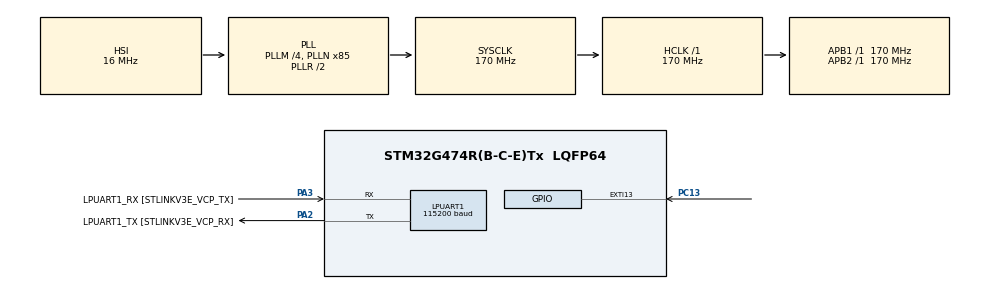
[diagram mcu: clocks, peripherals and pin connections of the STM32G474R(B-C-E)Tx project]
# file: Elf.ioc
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LPUART1.BaudRate=115200
Mcu.Family=STM32G4
Mcu.Name=STM32G474R(B-C-E)Tx
Mcu.Package=LQFP64
NVIC.EXTI15_10_IRQn=true\:0\:0\:false\:false\:false\:true\:true\:true
NVIC.PriorityGroup=NVIC_PRIORITYGROUP_4
NVIC.TIM3_IRQn=true\:0\:0\:false\:false\:false\:true\:true\:true
PA13.GPIO_Label=T_SWDIO
PA13.Signal=SYS_JTMS-SWDIO
PA14.GPIO_Label=T_SWCLK
PA14.Signal=SYS_JTCK-SWCLK
PA2.GPIO_Label=LPUART1_TX [STLINKV3E_VCP_RX]
PA2.Mode=Asynchronous
PA2.Signal=LPUART1_TX
PA3.GPIO_Label=LPUART1_RX [STLINKV3E_VCP_TX]
PA3.Mode=Asynchronous
PA3.Signal=LPUART1_RX
PA5.Signal=S_TIM2_CH1
PB3.GPIO_Label=T_SWO
PB3.Signal=SYS_JTDO-SWO
PC13.Signal=GPXTI13
PC14-OSC32_IN.GPIO_Label=RCC_OSC32_IN
PC14-OSC32_IN.Signal=RCC_OSC32_IN
PC15-OSC32_OUT.GPIO_Label=RCC_OSC32_OUT
PC15-OSC32_OUT.Signal=RCC_OSC32_OUT
PF0-OSC_IN.GPIO_Label=RCC_OSC_IN
PF0-OSC_IN.Signal=RCC_OSC_IN
PF1-OSC_OUT.GPIO_Label=RCC_OSC_OUT
PF1-OSC_OUT.Signal=RCC_OSC_OUT
ProjectManager.HeapSize=0x200
ProjectManager.StackSize=0x400
ProjectManager.TargetToolchain=STM32CubeIDE
RCC.ADC12Freq_Value=170000000
RCC.ADC345Freq_Value=170000000
RCC.AHBFreq_Value=170000000
RCC.APB1Freq_Value=170000000
RCC.APB1TimFreq_Value=170000000
RCC.APB2Freq_Value=170000000
RCC.APB2TimFreq_Value=170000000
RCC.CortexFreq_Value=170000000
RCC.EXTERNAL_CLOCK_VALUE=12288000
RCC.HCLKFreq_Value=170000000
RCC.HSE_VALUE=24000000
RCC.HSI48_VALUE=48000000
RCC.HSI_VALUE=16000000
RCC.LSE_VALUE=32768
RCC.PLLM=RCC_PLLM_DIV4
RCC.PLLN=85
RCC.RTCClockSelection=RCC_RTCCLKSOURCE_LSE
RCC.SYSCLKFreq_VALUE=170000000
RCC.SYSCLKSource=RCC_SYSCLKSOURCE_PLLCLK
RCC.USBFreq_Value=170000000
RCC.VCOOutputFreq_Value=340000000
SH.S_TIM2_CH1.0=TIM2_CH1
TIM2.Channel-PWM\ Generation1\ No\ Output=TIM_CHANNEL_1
VP_SYS_VS_DBSignals.Mode=DisableDeadBatterySignals
VP_TIM2_VS_ClockSourceINT.Mode=Internal
VP_TIM2_VS_no_output1.Mode=PWM Generation1 No Output
VP_TIM3_VS_ClockSourceINT.Mode=Internal
board=NUCLEO-G474RE

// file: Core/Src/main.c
/* USER CODE BEGIN Header */
/**
  ******************************************************************************
  * @file           : main.c
  * @brief          : Main program body
  ******************************************************************************
  * @attention
  *
  * Copyright (c) 2026 STMicroelectronics.
  * All rights reserved.
  *
  * This software is licensed under terms that can be found in the LICENSE file
  * in the root directory of this software component.
  * If no LICENSE file comes with this software, it is provided AS-IS.
  *
  ******************************************************************************
  */
/* USER CODE END Header */
#include "main.h"

/* USER CODE BEGIN Includes */
#include <stdio.h>
/* USER CODE END Includes */

/* USER CODE BEGIN PD */

typedef enum {
    HEALTHY,
    WARNING,
    ANGRY
} PetState;
/* USER CODE END PD */

UART_HandleTypeDef hlpuart1;

TIM_HandleTypeDef htim2;
TIM_HandleTypeDef htim3;

/* USER CODE BEGIN PV */

volatile uint32_t sedentary_sec = 0;
volatile uint8_t checkin_flag = 0;
/* USER CODE END PV */

void SystemClock_Config(void);
static void MX_GPIO_Init(void);
static void MX_TIM2_Init(void);
static void MX_TIM3_Init(void);
static void MX_LPUART1_UART_Init(void);

/* USER CODE BEGIN 0 */

void UART_SendString(char* str) {
    while (*str) {

        while ((LPUART1->ISR & USART_ISR_TXE) == 0) {}
        LPUART1->TDR = *str++;
    }
}

void TIM3_IRQHandler(void) {

    if (TIM3->SR & TIM_SR_UIF) {
        TIM3->SR &= ~TIM_SR_UIF;
        sedentary_sec++;
    }
}

void EXTI15_10_IRQHandler(void) {

    if (EXTI->PR1 & (1 << 13)) {
        EXTI->PR1 = (1 << 13);
        sedentary_sec = 0;
        checkin_flag = 1;
    }
}

void Set_LED_Speed(PetState state) {
    if (state == HEALTHY) {

        TIM2->PSC = 1700 - 1;
        TIM2->ARR = 1000 - 1;
    } else if (state == WARNING) {

        TIM2->PSC = 850 - 1;
        TIM2->ARR = 500 - 1;
    } else {

        TIM2->PSC = 170 - 1;
        TIM2->ARR = 100 - 1;
    }
}
/* USER CODE END 0 */

int main(void)
{

  /* MCU Configuration--------------------------------------------------------*/

  /* Reset of all peripherals, Initializes the Flash interface and the Systick. */
  HAL_Init();

  /* Configure the system clock */
  SystemClock_Config();

  /* Initialize all configured peripherals */
  MX_GPIO_Init();
  MX_TIM2_Init();
  MX_TIM3_Init();
  MX_LPUART1_UART_Init();
  /* USER CODE BEGIN 2 */
    /* USER CODE BEGIN 2 */
  HAL_Init();
  SystemClock_Config();
  MX_GPIO_Init();
  MX_LPUART1_UART_Init();

    TIM3->PSC = 17000 - 1;
    TIM3->ARR = 5000 - 1;
    TIM3->DIER |= TIM_DIER_UIE;
    TIM3->CR1 |= TIM_CR1_CEN;
    NVIC_EnableIRQ(TIM3_IRQn);
    NVIC_EnableIRQ(EXTI15_10_IRQn);

    Set_LED_Speed(HEALTHY);
    TIM2->EGR |= TIM_EGR_UG;

    TIM2->CCMR1 &= ~TIM_CCMR1_OC1M_Msk;
    TIM2->CCMR1 |= (0x6 << TIM_CCMR1_OC1M_Pos);
    TIM2->CCER |= TIM_CCER_CC1E;
    TIM2->CR1 |= TIM_CR1_CEN;

    for (volatile int i = 0; i < 500000; i++);
    UART_SendString("\r\n=== 久坐健康精靈 開機完成 ===\r\n");

    PetState current_state = HEALTHY;
    int32_t ccr_val = 0;
    int8_t ccr_step = 1;
  /* USER CODE END 2 */

  /* Infinite loop */
  while (1)
  {

    /* USER CODE BEGIN 3 */

	        if (checkin_flag) {
	            checkin_flag = 0;
	            if (current_state != HEALTHY) {
	                current_state = HEALTHY;
	                Set_LED_Speed(HEALTHY);
	                UART_SendString("感謝安撫！精靈已恢復健康，重新計時。\r\n");
	            }
	        }

	        if (sedentary_sec > 30 && current_state != ANGRY) {
	            current_state = ANGRY;
	            UART_SendString("【警告】精靈非常生氣！你已經坐超過 30 秒了！\r\n");
	        }
	        else if (sedentary_sec > 15 && sedentary_sec <= 30 && current_state == HEALTHY) {
	            current_state = WARNING;
	            UART_SendString("【提醒】精靈不開心了，久坐超過 15 秒，該起來喝水囉！\r\n");
	        }

	        if (current_state == HEALTHY) {
	            ccr_step = (ccr_step > 0) ? 1 : -1;
	        } else if (current_state == WARNING) {
	            ccr_step = (ccr_step > 0) ? 5 : -5;
	        } else {
	            ccr_step = (ccr_step > 0) ? 50 : -50;
	        }

	        ccr_val += ccr_step;

	        if (ccr_val >= 1000) {
	            ccr_val = 1000;
	            ccr_step = -ccr_step;
	        } else if (ccr_val <= 0) {
	            ccr_val = 0;
	            ccr_step = -ccr_step;
	        }

	        TIM2->CCR1 = ccr_val;

	        for (volatile int i = 0; i < 10000; i++);
  }
  /* USER CODE END 3 */
}

void SystemClock_Config(void)
{
  RCC_OscInitTypeDef RCC_OscInitStruct = {0};
  RCC_ClkInitTypeDef RCC_ClkInitStruct = {0};

  /** Configure the main internal regulator output voltage
  */
  HAL_PWREx_ControlVoltageScaling(PWR_REGULATOR_VOLTAGE_SCALE1_BOOST);

  /** Initializes the RCC Oscillators according to the specified parameters
  * in the RCC_OscInitTypeDef structure.
  */
  RCC_OscInitStruct.OscillatorType = RCC_OSCILLATORTYPE_HSI;
  RCC_OscInitStruct.HSIState = RCC_HSI_ON;
  RCC_OscInitStruct.HSICalibrationValue = RCC_HSICALIBRATION_DEFAULT;
  RCC_OscInitStruct.PLL.PLLState = RCC_PLL_ON;
  RCC_OscInitStruct.PLL.PLLSource = RCC_PLLSOURCE_HSI;
  RCC_OscInitStruct.PLL.PLLM = RCC_PLLM_DIV4;
  RCC_OscInitStruct.PLL.PLLN = 85;
  RCC_OscInitStruct.PLL.PLLP = RCC_PLLP_DIV2;
  RCC_OscInitStruct.PLL.PLLQ = RCC_PLLQ_DIV2;
  RCC_OscInitStruct.PLL.PLLR = RCC_PLLR_DIV2;
  if (HAL_RCC_OscConfig(&RCC_OscInitStruct) != HAL_OK)
  {
    Error_Handler();
  }

  /** Initializes the CPU, AHB and APB buses clocks
  */
  RCC_ClkInitStruct.ClockType = RCC_CLOCKTYPE_HCLK|RCC_CLOCKTYPE_SYSCLK
                              |RCC_CLOCKTYPE_PCLK1|RCC_CLOCKTYPE_PCLK2;
  RCC_ClkInitStruct.SYSCLKSource = RCC_SYSCLKSOURCE_PLLCLK;
  RCC_ClkInitStruct.AHBCLKDivider = RCC_SYSCLK_DIV1;
  RCC_ClkInitStruct.APB1CLKDivider = RCC_HCLK_DIV1;
  RCC_ClkInitStruct.APB2CLKDivider = RCC_HCLK_DIV1;

  if (HAL_RCC_ClockConfig(&RCC_ClkInitStruct, FLASH_LATENCY_4) != HAL_OK)
  {
    Error_Handler();
  }
}

static void MX_LPUART1_UART_Init(void)
{

  hlpuart1.Instance = LPUART1;
  hlpuart1.Init.BaudRate = 115200;
  hlpuart1.Init.WordLength = UART_WORDLENGTH_8B;
  hlpuart1.Init.StopBits = UART_STOPBITS_1;
  hlpuart1.Init.Parity = UART_PARITY_NONE;
  hlpuart1.Init.Mode = UART_MODE_TX_RX;
  hlpuart1.Init.HwFlowCtl = UART_HWCONTROL_NONE;
  hlpuart1.Init.OneBitSampling = UART_ONE_BIT_SAMPLE_DISABLE;
  hlpuart1.Init.ClockPrescaler = UART_PRESCALER_DIV1;
  hlpuart1.AdvancedInit.AdvFeatureInit = UART_ADVFEATURE_NO_INIT;
  if (HAL_UART_Init(&hlpuart1) != HAL_OK)
  {
    Error_Handler();
  }
  if (HAL_UARTEx_SetTxFifoThreshold(&hlpuart1, UART_TXFIFO_THRESHOLD_1_8) != HAL_OK)
  {
    Error_Handler();
  }
  if (HAL_UARTEx_SetRxFifoThreshold(&hlpuart1, UART_RXFIFO_THRESHOLD_1_8) != HAL_OK)
  {
    Error_Handler();
  }
  if (HAL_UARTEx_DisableFifoMode(&hlpuart1) != HAL_OK)
  {
    Error_Handler();
  }

}

static void MX_TIM2_Init(void)
{

  TIM_ClockConfigTypeDef sClockSourceConfig = {0};
  TIM_MasterConfigTypeDef sMasterConfig = {0};
  TIM_OC_InitTypeDef sConfigOC = {0};

  htim2.Instance = TIM2;
  htim2.Init.Prescaler = 0;
  htim2.Init.CounterMode = TIM_COUNTERMODE_UP;
  htim2.Init.Period = 4294967295;
  htim2.Init.ClockDivision = TIM_CLOCKDIVISION_DIV1;
  htim2.Init.AutoReloadPreload = TIM_AUTORELOAD_PRELOAD_DISABLE;
  if (HAL_TIM_Base_Init(&htim2) != HAL_OK)
  {
    Error_Handler();
  }
  sClockSourceConfig.ClockSource = TIM_CLOCKSOURCE_INTERNAL;
  if (HAL_TIM_ConfigClockSource(&htim2, &sClockSourceConfig) != HAL_OK)
  {
    Error_Handler();
  }
  if (HAL_TIM_PWM_Init(&htim2) != HAL_OK)
  {
    Error_Handler();
  }
  sMasterConfig.MasterOutputTrigger = TIM_TRGO_RESET;
  sMasterConfig.MasterSlaveMode = TIM_MASTERSLAVEMODE_DISABLE;
  if (HAL_TIMEx_MasterConfigSynchronization(&htim2, &sMasterConfig) != HAL_OK)
  {
    Error_Handler();
  }
  sConfigOC.OCMode = TIM_OCMODE_PWM1;
  sConfigOC.Pulse = 0;
  sConfigOC.OCPolarity = TIM_OCPOLARITY_HIGH;
  sConfigOC.OCFastMode = TIM_OCFAST_DISABLE;
  if (HAL_TIM_PWM_ConfigChannel(&htim2, &sConfigOC, TIM_CHANNEL_1) != HAL_OK)
  {
    Error_Handler();
  }

}

static void MX_TIM3_Init(void)
{

  TIM_ClockConfigTypeDef sClockSourceConfig = {0};
  TIM_MasterConfigTypeDef sMasterConfig = {0};

  htim3.Instance = TIM3;
  htim3.Init.Prescaler = 0;
  htim3.Init.CounterMode = TIM_COUNTERMODE_UP;
  htim3.Init.Period = 65535;
  htim3.Init.ClockDivision = TIM_CLOCKDIVISION_DIV1;
  htim3.Init.AutoReloadPreload = TIM_AUTORELOAD_PRELOAD_DISABLE;
  if (HAL_TIM_Base_Init(&htim3) != HAL_OK)
  {
    Error_Handler();
  }
  sClockSourceConfig.ClockSource = TIM_CLOCKSOURCE_INTERNAL;
  if (HAL_TIM_ConfigClockSource(&htim3, &sClockSourceConfig) != HAL_OK)
  {
    Error_Handler();
  }
  sMasterConfig.MasterOutputTrigger = TIM_TRGO_RESET;
  sMasterConfig.MasterSlaveMode = TIM_MASTERSLAVEMODE_DISABLE;
  if (HAL_TIMEx_MasterConfigSynchronization(&htim3, &sMasterConfig) != HAL_OK)
  {
    Error_Handler();
  }

}

static void MX_GPIO_Init(void)
{
  GPIO_InitTypeDef GPIO_InitStruct = {0};

  /* GPIO Ports Clock Enable */
  __HAL_RCC_GPIOC_CLK_ENABLE();
  __HAL_RCC_GPIOF_CLK_ENABLE();
  __HAL_RCC_GPIOA_CLK_ENABLE();
  __HAL_RCC_GPIOB_CLK_ENABLE();

  /*Configure GPIO pin : PC13 */
  GPIO_InitStruct.Pin = GPIO_PIN_13;
  GPIO_InitStruct.Mode = GPIO_MODE_IT_RISING;
  GPIO_InitStruct.Pull = GPIO_NOPULL;
  HAL_GPIO_Init(GPIOC, &GPIO_InitStruct);

  /* EXTI interrupt init*/
  HAL_NVIC_SetPriority(EXTI15_10_IRQn, 0, 0);
  HAL_NVIC_EnableIRQ(EXTI15_10_IRQn);

}

void Error_Handler(void)
{
  __disable_irq();
  while (1)
  {
  }
}
